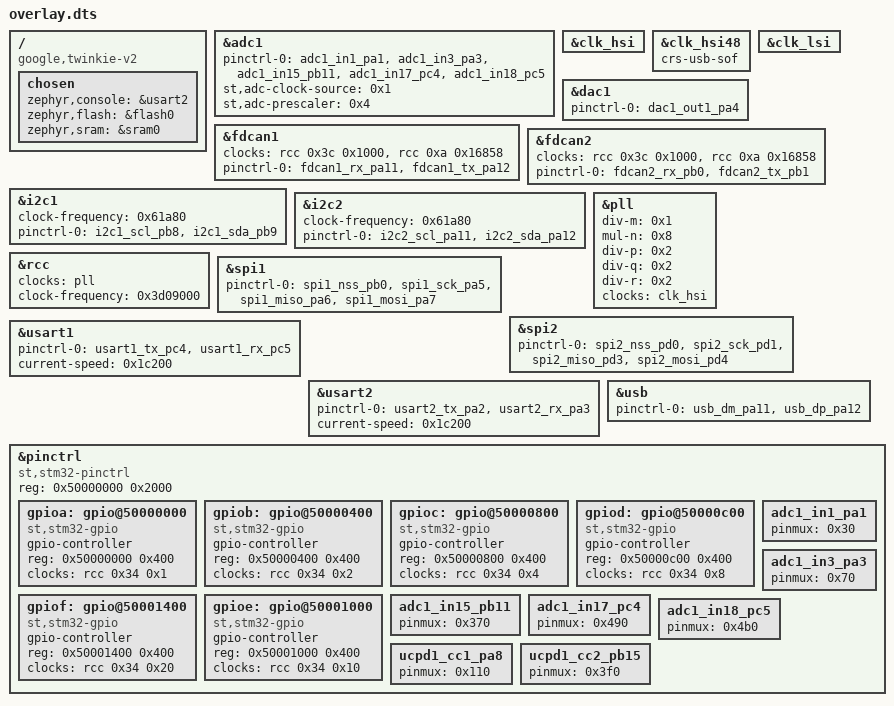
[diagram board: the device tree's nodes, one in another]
/ {
	compatible = "google,twinkie-v2";
	chosen {
		zephyr,console = &usart2;
		zephyr,flash = &flash0;
		zephyr,sram = &sram0;
	};
};
&adc1{
	status = "okay";
	#address-cells = < 0x1 >;
	#size-cells = < 0x0 >;
	pinctrl-0 = < &adc1_in1_pa1 &adc1_in3_pa3 &adc1_in15_pb11 &adc1_in17_pc4 &adc1_in18_pc5 >;
	pinctrl-names = "default";
	st,adc-clock-source = < 0x1 >;
	st,adc-prescaler = < 0x4 >;
};
&clk_hsi{
	status = "okay";
};
&clk_hsi48{
	status = "okay";
	crs-usb-sof;
};
&clk_lsi{
	status = "okay";
};
&dac1{
	status = "okay";
	pinctrl-0 = < &dac1_out1_pa4 >;
	pinctrl-names = "default";
};
&fdcan1{
	clocks = < &rcc 0x3c 0x1000 >, < &rcc 0xa 0x16858 >;
	status = "okay";
	pinctrl-0 = < &fdcan1_rx_pa11 &fdcan1_tx_pa12 >;
	pinctrl-names = "default";
};
&fdcan2{
	clocks = < &rcc 0x3c 0x1000 >, < &rcc 0xa 0x16858 >;
	status = "okay";
	pinctrl-0 = < &fdcan2_rx_pb0 &fdcan2_tx_pb1 >;
	pinctrl-names = "default";
};
&i2c1{
	clock-frequency = < 0x61a80 >;
	status = "okay";
	pinctrl-0 = < &i2c1_scl_pb8 &i2c1_sda_pb9 >;
	pinctrl-names = "default";
};
&i2c2{
	clock-frequency = < 0x61a80 >;
	status = "okay";
	pinctrl-0 = < &i2c2_scl_pa11 &i2c2_sda_pa12 >;
	pinctrl-names = "default";
};
&pll{
	status = "okay";
	div-m = < 0x1 >;
	mul-n = < 0x8 >;
	div-p = < 0x2 >;
	div-q = < 0x2 >;
	div-r = < 0x2 >;
	clocks = < &clk_hsi >;
};
&rcc{
	clocks = < &pll >;
	clock-frequency = < 0x3d09000 >;
};
&spi1{
	status = "okay";
	pinctrl-0 = < &spi1_nss_pb0 &spi1_sck_pa5 &spi1_miso_pa6 &spi1_mosi_pa7 >;
	pinctrl-names = "default";
};
&spi2{
	status = "okay";
	pinctrl-0 = < &spi2_nss_pd0 &spi2_sck_pd1 &spi2_miso_pd3 &spi2_mosi_pd4 >;
	pinctrl-names = "default";
};
&usart1{
	status = "okay";
	pinctrl-0 = < &usart1_tx_pc4 &usart1_rx_pc5 >;
	pinctrl-names = "default";
	current-speed = < 0x1c200 >;
};
&usart2{
	status = "okay";
	pinctrl-0 = < &usart2_tx_pa2 &usart2_rx_pa3 >;
	pinctrl-names = "default";
	current-speed = < 0x1c200 >;
};
&usb{
	status = "okay";
	pinctrl-0 = < &usb_dm_pa11 &usb_dp_pa12 >;
	pinctrl-names = "default";
};
&pinctrl{
	compatible = "st,stm32-pinctrl";
	#address-cells = < 0x1 >;
	#size-cells = < 0x1 >;
	reg = < 0x50000000 0x2000 >;
	gpioa: gpio@50000000 {
		compatible = "st,stm32-gpio";
		gpio-controller;
		#gpio-cells = < 0x2 >;
		reg = < 0x50000000 0x400 >;
		clocks = < &rcc 0x34 0x1 >;
	};
	gpiob: gpio@50000400 {
		compatible = "st,stm32-gpio";
		gpio-controller;
		#gpio-cells = < 0x2 >;
		reg = < 0x50000400 0x400 >;
		clocks = < &rcc 0x34 0x2 >;
	};
	gpioc: gpio@50000800 {
		compatible = "st,stm32-gpio";
		gpio-controller;
		#gpio-cells = < 0x2 >;
		reg = < 0x50000800 0x400 >;
		clocks = < &rcc 0x34 0x4 >;
	};
	gpiod: gpio@50000c00 {
		compatible = "st,stm32-gpio";
		gpio-controller;
		#gpio-cells = < 0x2 >;
		reg = < 0x50000c00 0x400 >;
		clocks = < &rcc 0x34 0x8 >;
	};
	gpiof: gpio@50001400 {
		compatible = "st,stm32-gpio";
		gpio-controller;
		#gpio-cells = < 0x2 >;
		reg = < 0x50001400 0x400 >;
		clocks = < &rcc 0x34 0x20 >;
	};
	gpioe: gpio@50001000 {
		compatible = "st,stm32-gpio";
		gpio-controller;
		#gpio-cells = < 0x2 >;
		reg = < 0x50001000 0x400 >;
		clocks = < &rcc 0x34 0x10 >;
	};
	adc1_in1_pa1: adc1_in1_pa1 {
		pinmux = < 0x30 >;
	};
	adc1_in3_pa3: adc1_in3_pa3 {
		pinmux = < 0x70 >;
	};
	adc1_in15_pb11: adc1_in15_pb11 {
		pinmux = < 0x370 >;
	};
	adc1_in17_pc4: adc1_in17_pc4 {
		pinmux = < 0x490 >;
	};
	adc1_in18_pc5: adc1_in18_pc5 {
		pinmux = < 0x4b0 >;
	};
	ucpd1_cc1_pa8: ucpd1_cc1_pa8 {
		pinmux = < 0x110 >;
	};
	ucpd1_cc2_pb15: ucpd1_cc2_pb15 {
		pinmux = < 0x3f0 >;
	};
};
